# RN821X_RN721X_SOC_V3 register map
File version: v1.0.4
CPU: CM0 r0p0, little endian, no MPU, no FPU, 3 interrupt priority bits
Registers are 32-bit, read-write, reset 0x0 unless marked. A register's access mark holds for its fields unless they carry their own. Offsets are from the block's base; [hi:lo] are bit positions; {n}, {i} and the like mark numbered series; 'fields as' and 'values as' point back to an identical list.

## TC1 — A 32-bit timer
Base 0x40014000
0x00 CNT ro — current counting value register
  [31:0] CNT — current Timer counter value bits
0x04 PS — prescaler value register of the counter clock
  [15:0] PS — prescaler value bits of the counter clock
0x0C DN — target counting value register
  [31:0] DN — target counting value bits
0x14 CCD0 — capture(compare) channel No.0 data register
  [31:0] CCD0 — capture(compare) channel No.0 data bits
0x18 CCD1 — capture(compare) channel No.1 data register
  [31:0] CCD1 — capture(compare) channel No.1 data bits
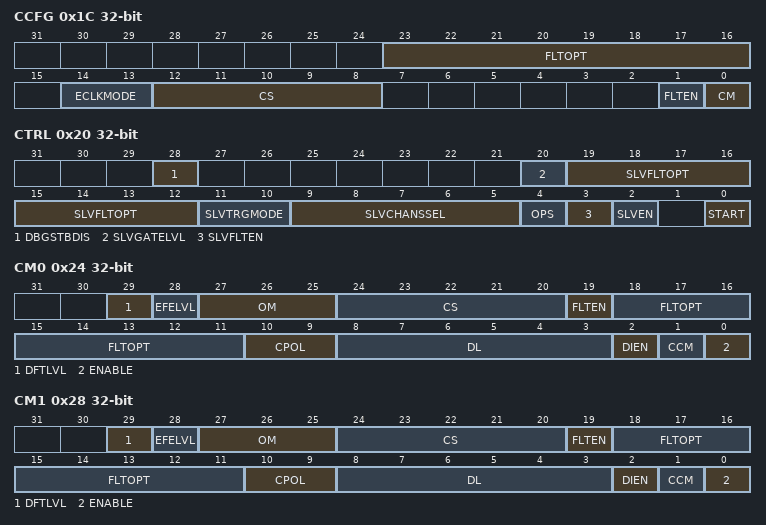
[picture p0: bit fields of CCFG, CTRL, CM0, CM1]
0x1C CCFG — clock config register
  [23:16] FLTOPT — external clock source filter clock cycles set bits
  [14:13] ECLKMODE — external clock mode selection bits
    0=PE (every posedge found on input recognized as a couting event); 1=NE (every negedge found on input recognized as a couting event); 2=BE (both posedge and negedge found on input recognized as a as a couting event)
  [12:8] CS — external clock source selection bits
    {v}=UART{v}_RXD (select UART{v} RXD) (v=0..3); 4=OTHTC_OUTN0 (select negative output of channel 0 of the other TC (TC1/TC0)); 5=OTHTC_OUTP0 (select positive output of channel 0 of the other TC (TC1/TC0)); 6=OTHTC_OUTN1 (select negative output of channel 1 of the other TC (TC1/TC0)); 7=OTHTC_OUTP1 (select positive output of channel 1 of the other TC (TC1/TC0)); 8=UART4_RXD (select UART4_RXD); 9=UART5_RXD (select UART5_RXD); 10=78160_P41 (select iso7816 channel No.0 input(P41)); 11=78161_P42 (select iso7816 channel No.1 dual-direction input(P42)); 12=78161_P43 (select iso7816 channel No.1 single-direction input(P43)); 16=SF_OUT (select apparent power pulse output); 17=QF_OUT (select reactive power pulse output); 18=PF_OUT (select active power pulse output); 19=RTC_OUT (select rtc output); 20=P10 (select P1[0]); 21=P11 (select P1[1]); {v}=P{v-10}_P{v+30} (select P1[{v-20}] or P5[{v-20}]) (v=22..27); 28=P30 (select P3[0]); 29=P31 (select P3[1]); 30=P33 (select P3[3]); 31=P35 (select P3[5])
  [1] FLTEN — external clock source filter enable bit
  [0] CM — clock mode selection bit
    0=INT (using on-chip system clock as input counting clock); 1=EXT (using external clock(to the timer) as input counting clock(refer to bitfield CS of register TC_CCFG for clock selection))
0x20 CTRL — control register
  [28] DBGSTBDIS — debugger halt standby enable/disable bit
    0=DIS (halt counting when SoC halted by debugger); 1=EN (keep counting when SoC halted by debugger)
  [20] SLVGATELVL — slave mode gating level control bit
    0=LOW (select low level sensitive gate); 1=HIGH (select high level sensitive gate)
  [19:12] SLVFLTOPT — slave mode input filter parameter configuration bits
  [11:10] SLVTRGMODE — slave mode polarity control selection bits
    0=PE (clean internal counter at posedge); 1=NE (clean internal counter at negedge); 2=BE (clean internal counter at both posedge and negedge); 3=GM (level sensitive gate control)
  [9:5] SLVCHANSSEL — slave mode input selection bits
    values as CCFG.CS
  [4] OPS — one pulse mode selection bit
    0=DIS (one pulse mode disabled(timer continue counting when overflow)); 1=EN (one pulse mode enabled(timer stop counting when overflow))
  [3] SLVFLTEN — slave mode input filter enable
  [2] SLVEN — slave mode enable
  [0] START — timer start bit
0x24 CM0 — capture(compare) channel No.0 mode register
  [29] DFTLVL — compare valid default level set bit
  [28] EFELVL — compare valid output level set bit
  [27:25] OM — compare output mode cfg bits
    0=NUL (no output generated); 1=VL (set as valid level); 2=INVL (set as invalid level); 3=TOG (toggle output); 4=FVL (force as valid level); 5=FINVL (force as invalid level); 6=PWM1 (when tc_cnt less than tc_ccdx, set output as valid level); 7=PWM2 (when tc_cnt greater than tc_ccdx, set output as valid level)
  [24:20] CS — capture channel selection bits
    values as CCFG.CS
  [19] FLTEN — capture filter enable bit
  [18:11] FLTOPT — capture filter parameter set bits
  [10:9] CPOL — capture polarity selection bits
    0=PE (capture on posedge); 1=NE (capture on negedge); 2=BE (capture on both posedge and negedge)
  [8:3] DL — compare dead zone length configuration bits (only for PWM1/PWM2)
  [2] DIEN — compare dead zone insertion enable bit (only for PWM1/PWM2)
  [1] CCM — capture(compare) selection bit
  [0] ENABLE — channel enable bit
0x28 CM1 — capture(compare) channel No.1 mode register
  fields as CM0
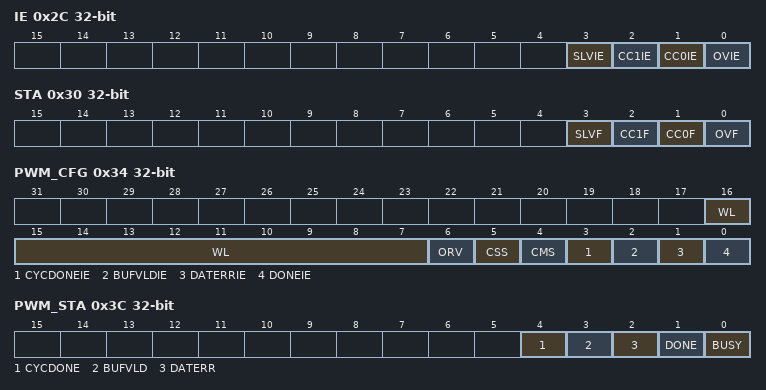
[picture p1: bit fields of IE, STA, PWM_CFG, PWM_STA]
0x2C IE — Interrupt enable register
  [3] SLVIE — slave interrupt enable
  [2] CC1IE — compare(caputure) channel No.1 interrupt enable
  [1] CC0IE — compare(caputure) channel No.0 interrupt enable
  [0] OVIE — overflow interrupt enable
0x30 STA — status register
  [3] SLVF write-1-clears — slave event flag
  [2] CC1F write-1-clears — compare(capture) channel No.1 flag
  [1] CC0F write-1-clears — compare(capture) channel No.0 flag
  [0] OVF write-1-clears — overflow interrupt flag
0x34 PWM_CFG — PWM config register
  [16:7] WL — PWM wave length config bits (available when ORV=0)
  [6] ORV — PWM output remain period mode selection bit
    0=WLC (wave length configurable); 1=ORV (output remain valid)
  [5] CSS — PWM complete signal selection bit
    0=CS (select to finish output last complete signal while module disabled); 1=BS (select to break output signal while module disabled)
  [4] CMS — PWM control mode selection bit
    0=DMA (select as DMA mode); 1=SOFT (select as soft control mode)
  [3] CYCDONEIE — output cycle done interrupt enable bit
    0=DIS (disable); 1=EN (enable)
  [2] BUFVLDIE — PWM buffer empty interrupt enable bit (only soft mode available)
    0=DIS (disable); 1=EN (enable)
  [1] DATERRIE — data error interrupt enable bit
    0=DIS (disable); 1=EN (enable)
  [0] DONEIE — PWM output done interrupt enable bit
    0=DIS (disable); 1=EN (enable)
0x38 PWM_CTRL — PWM control register
  [0] EN — PWM enable bit
0x3C PWM_STA — PWM status register
  [4] CYCDONE write-1-clears — PWM output cycle done interrupt flag
  [3] BUFVLD write-1-clears — PWM buffer empty interrupt flag
  [2] DATERR write-1-clears — PWM data error interrupt flag
  [1] DONE write-1-clears — PWM output done interrupt flag
  [0] BUSY — PWM output busy flag
0x40 PWM_CNT — PWM current counting value register
  [15:0] N_PWM — PWM cycle Timer counter value bits
0x44 PWM_DMA_BADR — PWM DMA base address register
  [14:0] BADR — DMA begin addr configuration bits
0x48 PWM_DMA_LEN — PWM DMA length register
  [14:0] LEN — DMA length configuration bits
0x4C PWM_DMA_ADR ro — PWM DMA current address register
  [14:0] ADR — current DMA addr bits
